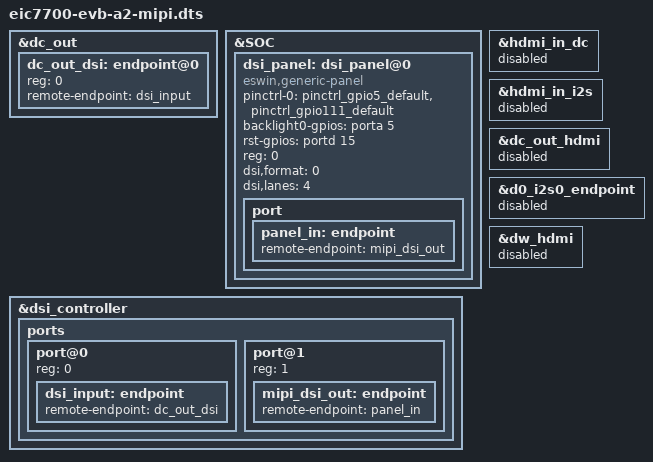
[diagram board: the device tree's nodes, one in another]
/dts-v1/;
/plugin/;

#include <dt-bindings/gpio/gpio.h>
/ {
	fragment@0 {
		target =  <&dc_out>;
		__overlay__ {
			dc_out_dsi: endpoint@0 {
				reg = <0>;
				remote-endpoint = <&dsi_input>;
			};
		};
	};

	fragment@1 {
		target =  <&SOC>;
		__overlay__ {
			dsi_panel:dsi_panel@0 {
				compatible = "eswin,generic-panel";
				status = "okay";
				pinctrl-names = "default";
				pinctrl-0 = <&pinctrl_gpio5_default &pinctrl_gpio111_default>;
				backlight0-gpios = <&porta 5 GPIO_ACTIVE_HIGH>;
				rst-gpios = <&portd 15 GPIO_ACTIVE_HIGH>;
				reg = <0>;
				dsi,format = <0>; //RGB888:0, RGB666:1, RGB565:3
				dsi,lanes = <4>;
				port {
					panel_in: endpoint {
						remote-endpoint = <&mipi_dsi_out>;
					};
				};
			};
		};
	};

    fragment@2 {
		target =  <&dsi_controller>;
		__overlay__ {
			status = "okay";
			ports {
				#address-cells = <1>;
				#size-cells = <0>;
				port@0 {
					#address-cells = <1>;
					#size-cells = <0>;
					reg = <0>;
					dsi_input: endpoint {
						remote-endpoint = <&dc_out_dsi>;
					};
				};
				port@1 {
					#address-cells = <1>;
					#size-cells = <0>;
					reg = <1>;
					mipi_dsi_out: endpoint {
						remote-endpoint = <&panel_in>;
					};
				};
			};
		};
	};

	fragment@3{
		target =  <&hdmi_in_dc>;
		__overlay__ {
			status = "disabled";
		};
	};

	fragment@4{
		target =  <&hdmi_in_i2s>;
		__overlay__ {
			status = "disabled";
		};
	};


	fragment@5{
		target =  <&dc_out_hdmi>;
		__overlay__ {
			status = "disabled";
		};
	};

	fragment@6{
		target =  <&d0_i2s0_endpoint>;
		__overlay__ {
			status = "disabled";
		};
	};

	fragment@7{
		target =  <&dw_hdmi>;
		__overlay__ {
			status = "disabled";
		};
	};
};
